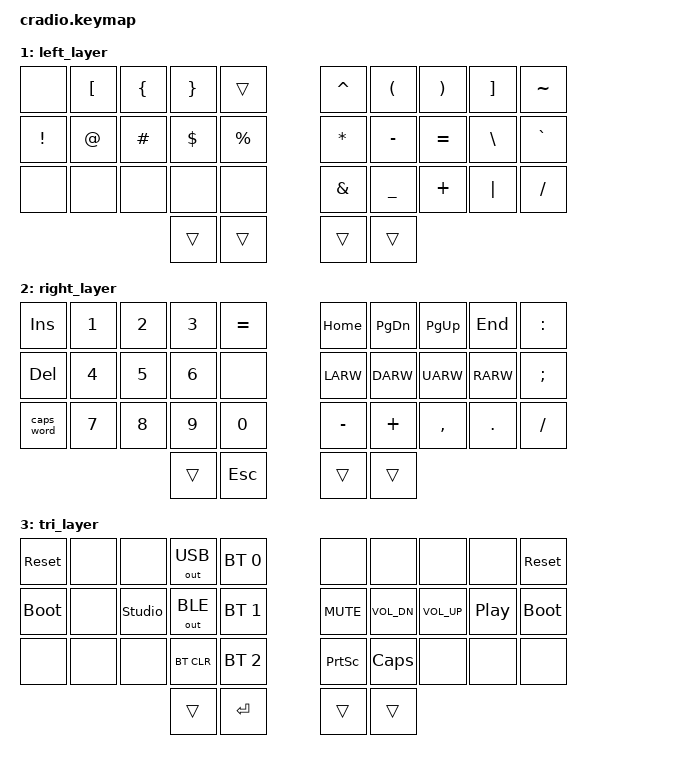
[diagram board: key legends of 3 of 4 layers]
// Copyright (c) 2022 The ZMK Contributors
// SPDX-License-Identifier: MIT

#include <behaviors.dtsi>
#include <dt-bindings/zmk/keys.h>
#include <dt-bindings/zmk/bt.h>
#include <dt-bindings/zmk/outputs.h>

// Home row mods macro
#define HRML(k1,k2,k3,k4) &ht LSHFT k1 &ht LALT k2 &ht LCTRL k3 &ht LGUI k4
#define HRMR(k1,k2,k3,k4) &ht RGUI k1 &ht RCTRL k2 &ht RALT k3 &ht RSHFT k4

/ {
    behaviors {
        ht: hold_tap {
            label = "hold_tap";
            compatible = "zmk,behavior-hold-tap";
            #binding-cells = <2>;
            flavor = "tap-preferred";
            tapping-term-ms = <220>;
            quick-tap-ms = <150>;
            global-quick-tap;
            bindings = <&kp>, <&kp>;
        };
    };

    conditional_layers {
        compatible = "zmk,conditional-layers";
        tri_layer {
            if-layers = <1 2>;
            then-layer = <3>;
        };
    };

    keymap {
        compatible = "zmk,keymap";
        default_layer {
            bindings = <
        //╭──────────┬──────────┬──────────┬──────────┬──────────╮   ╭──────────┬──────────┬──────────┬──────────┬──────────╮
        //│ Q        │ W        │ E        │ R        │ T        │   │ Y        │ U        │ I        │ O        │ P        │
            &kp Q      &kp W      &kp E      &kp R      &kp T          &kp Y      &kp U      &kp I      &kp O      &kp P
        //├──────────┼──────────┼──────────┼──────────┼──────────┤   ├──────────┼──────────┼──────────┼──────────┼──────────┤
        //│ SHIFT(A) │ ALT(S)   │ CTRL(D)  │ GUI(F)   │ G        │   │ H        │ GUI(J)   │ CTRL(K)  │ ALT(L)   │SHIFT(; :)│
            HRML(A,    S,         D,         F)         &kp G          &kp H      HRMR(J,    K,         L,         SEMI)
        //├──────────┼──────────┼──────────┼──────────┼──────────┤   ├──────────┼──────────┼──────────┼──────────┼──────────┤
        //│ Z        │ X        │ C        │ V        │ B        │   │ N        │ M        │ , <      │ . >      │ / ?      │
            &kp Z      &kp X      &kp C      &kp V      &kp B          &kp N      &kp M      &kp COMMA  &kp DOT    &kp FSLH
        //╰──────────┴──────────┴──────────┼──────────┼──────────┤   ├──────────┼──────────┼──────────┴──────────┴──────────╯
        //                                 │LEFT(TAB) │ ENTER    │   │ SPACE    │RIGHT(BSPC)│
                                             &lt 1 TAB  &kp ENTER      &kp SPACE  &lt 2 BSPC
        //                                 ╰──────────┴──────────╯   ╰──────────┴──────────╯
            >;
        };

        left_layer {
            bindings = <
        //╭──────────┬──────────┬──────────┬──────────┬──────────╮   ╭──────────┬──────────┬──────────┬──────────┬──────────╮
        //│          │ [ {      │ {        │ }        │          │   │ ^        │ (        │ )        │ ] }      │ ~        │
            &none      &kp LBKT   &kp LBRC   &kp RBRC   &trans         &kp CARET  &kp LPAR   &kp RPAR   &kp RBKT   &kp TILDE
        //├──────────┼──────────┼──────────┼──────────┼──────────┤   ├──────────┼──────────┼──────────┼──────────┼──────────┤
        //│ !        │ @        │ #        │ $        │ %        │   │ *        │ - _      │ = +      │ \ |      │ ` ~      │
            &kp EXCL   &kp AT     &kp HASH   &kp DLLR   &kp PRCNT      &kp ASTRK  &kp MINUS  &kp EQUAL  &kp BSLH   &kp GRAVE
        //├──────────┼──────────┼──────────┼──────────┼──────────┤   ├──────────┼──────────┼──────────┼──────────┼──────────┤
        //│          │          │          │          │          │   │ &        │ _        │ +        │ │        │ / ?      │
            &none      &none      &none      &none      &none          &kp AMPS   &kp UNDER  &kp PLUS   &kp PIPE   &kp FSLH
        //╰──────────┴──────────┴──────────┼──────────┼──────────┤   ├──────────┼──────────┼──────────┴──────────┴──────────╯
        //                                 │ TAB      │ ENTER    │   │ SPACE    │ BSPC     │
                                             &trans     &trans         &trans     &trans
        //                                 ╰──────────┴──────────╯   ╰──────────┴──────────╯
            >;
        };

        right_layer {
            bindings = <
        //╭──────────┬──────────┬──────────┬──────────┬──────────╮   ╭──────────┬──────────┬──────────┬──────────┬──────────╮
        //│ INSERT   │ 1 !      │ 2 @      │ 3 #      │ = +      │   │ HOME     │ PAGE DN  │ PAGE UP  │ END      │ :        │
            &kp INS    &kp N1     &kp N2     &kp N3     &kp EQUAL      &kp HOME   &kp PG_DN  &kp PG_UP  &kp END    &kp COLON
        //├──────────┼──────────┼──────────┼──────────┼──────────┤   ├──────────┼──────────┼──────────┼──────────┼──────────┤
        //│ DELETE   │ 4 $      │ 5 %      │ 6 ^      │          │   │ LEFT     │ DOWN     │ UP       │ RIGHT    │ ; :      │
            &kp DEL    &kp N4     &kp N5     &kp N6     &none          &kp LARW   &kp DARW   &kp UARW   &kp RARW   &kp SEMI
        //├──────────┼──────────┼──────────┼──────────┼──────────┤   ├──────────┼──────────┼──────────┼──────────┼──────────┤
        //│ CAPS     │ 7 &      │ 8 *      │ 9 (      │ 0 )      │   │ - _      │ +        │ , <      │ . >      │ / ?      │
           &caps_word  &kp N7     &kp N8     &kp N9     &kp N0         &kp MINUS  &kp PLUS   &kp COMMA  &kp DOT    &kp FSLH
        //╰──────────┴──────────┴──────────┼──────────┼──────────┤   ├──────────┼──────────┼──────────┴──────────┴──────────╯
        //                                 │ TAB      │ ESC      │   │ SPACE    │ BSPC     │
                                             &trans     &kp ESC        &trans     &trans
        //                                 ╰──────────┴──────────╯   ╰──────────┴──────────╯
            >;
        };

        tri_layer {
            bindings = <
        //╭──────────┬──────────┬──────────┬──────────┬──────────╮   ╭──────────┬──────────┬──────────┬──────────┬──────────╮
        //│ RESET    │          │          │ OUT USB  │ BT 0     │   │          │          │          │          │ RESET    │
            &sys_reset &none      &none    &out OUT_USB &bt BT_SEL 0   &none      &none      &none      &none      &sys_reset
        //├──────────┼──────────┼──────────┼──────────┼──────────┤   ├──────────┼──────────┼──────────┼──────────┼──────────┤
        //│BOOTLOADER│          │ STUDIO   │ OUT BT   │ BT 1     │   │ MUTE     │ VOL DN   │ VOL UP   │PLAY/PAUSE│BOOTLOADER│
           &bootloader &none  &studio_unlock &out OUT_BLE &bt BT_SEL 1 &kp K_MUTE &kp C_VOL_DN &kp C_VOL_UP &kp C_PLAY_PAUSE &bootloader
        //├──────────┼──────────┼──────────┼──────────┼──────────┤   ├──────────┼──────────┼──────────┼──────────┼──────────┤
        //│          │          │          │ CLEAR BT │ BT 2     │   │ PSCRN    │ CLCK     │          │          │          │
            &none      &none      &none     &bt BT_CLR &bt BT_SEL 2    &kp PSCRN  &kp CLCK   &none      &none      &none
        //╰──────────┴──────────┴──────────┼──────────┼──────────┤   ├──────────┼──────────┼──────────┴──────────┴──────────╯
        //                                 │ TAB      │ ENTER    │   │ SPACE    │ BSPC     │
                                             &trans     &kp ENTER      &trans     &trans
        //                                 ╰──────────┴──────────╯   ╰──────────┴──────────╯
            >;
        };
    };
};
